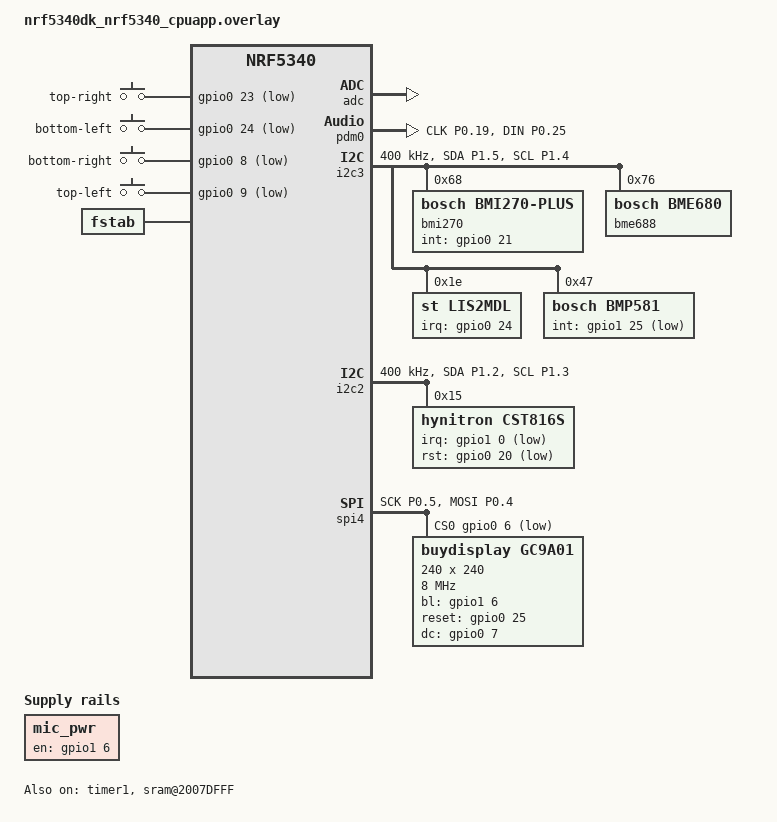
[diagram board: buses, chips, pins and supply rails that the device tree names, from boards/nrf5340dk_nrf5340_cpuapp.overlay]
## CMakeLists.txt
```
cmake_minimum_required(VERSION 3.20.0)

# Apply patches before build
function(apply_patches patch_dir target_dir)
    file(GLOB_RECURSE files RELATIVE ${CMAKE_SOURCE_DIR} "${patch_dir}/*.patch")
    foreach(file ${files})
        execute_process(
            COMMAND git apply --reverse --check ${CMAKE_CURRENT_SOURCE_DIR}/${file} --unsafe-paths
            WORKING_DIRECTORY ${target_dir}
            RESULT_VARIABLE patch_already_applied
            OUTPUT_QUIET
            ERROR_QUIET
        )
        if(patch_already_applied EQUAL 0)
            message("Patch already applied: ${file}")
        else()
            message("Applying patch: ${file}")
            execute_process(
                COMMAND git apply ${CMAKE_CURRENT_SOURCE_DIR}/${file} --unsafe-paths
                WORKING_DIRECTORY ${target_dir}
                RESULT_VARIABLE patch_apply_result
            )
            if(NOT patch_apply_result EQUAL 0)
                message(FATAL_ERROR "Failed to apply patch: ${file}")
            endif()
        endif()
    endforeach()
endfunction()

apply_patches("patches/zephyr" $ENV{ZEPHYR_BASE})
apply_patches("patches/ext_drivers" ${CMAKE_SOURCE_DIR}/src/ext_drivers)

# Get the target hardware
string(REGEX MATCH "zswatch@([0-9]+)/nrf5340.*" ZSWATCH_BOARD "${BOARD}")
if(ZSWATCH_BOARD)
    string(CONCAT VERSION_STRING "\"" ${CMAKE_MATCH_1} "\"")
    set(CONFIG_ZSWATCH_PCB_REV ${CMAKE_MATCH_1} CACHE INTERNAL "")
    set(CONFIG_BT_DIS_HW_REV_STR ${VERSION_STRING} CACHE INTERNAL "")

    message("PCB revision: " ${CONFIG_ZSWATCH_PCB_REV})
endif()

set(BOARD_ROOT ${CMAKE_CURRENT_SOURCE_DIR})

macro(app_set_runner_args)
    if (CONFIG_BOARD_ZSWATCH_NRF5340_CPUAPP AND CONFIG_BOARD_REVISION STREQUAL "5") 
        board_runner_args(nrfjprog "--qspiini=${CMAKE_CURRENT_SOURCE_DIR}/qspi_mx25u51245.ini")
    elseif(CONFIG_BOARD_ZSWATCH_NRF5340_CPUAPP AND CONFIG_BOARD_REVISION STREQUAL "4")
        board_runner_args(nrfjprog "--qspiini=${CMAKE_CURRENT_SOURCE_DIR}/qspi_at25sl128a.ini")
    else ()
        message("Uploading firmware to external flash may fail. Default ini will be used.")
    endif()
endmacro()

find_package(Zephyr REQUIRED HINTS $ENV{ZEPHYR_BASE})
project(ZSWatchFW)

zephyr_compile_definitions(
  -DNRF53_ERRATA_159_ENABLE_WORKAROUND=0 # Not allowing 128MHz CPU with QPSI at same time. We take the risk of this errata that may cause currupt QPSI data.
)

add_subdirectory(drivers)
add_subdirectory(src/history)
add_subdirectory(src/applications)
add_subdirectory(src/ui/watchfaces)
add_subdirectory(src/sensors)
add_subdirectory(src/sensor_fusion)
add_subdirectory(src/events)
add_subdirectory(src/managers)
add_subdirectory(src/drivers)
add_subdirectory(src/ble)
add_subdirectory(src/images)

include_directories(src/)
include_directories(src/ui)
include_directories(src/applications)
include_directories(src/ui/watchfaces)

if (CONFIG_DT_HAS_NORDIC_NPM1300_ENABLED)
    add_subdirectory(src/fuel_gauge)
else()
    add_subdirectory(src/basic_battery)
endif()

target_sources(app PRIVATE src/zsw_clock.c)
target_sources(app PRIVATE src/main.c)
target_sources(app PRIVATE src/zsw_cpu_freq.c)
target_sources(app PRIVATE src/zsw_retained_ram_storage.c)
target_sources(app PRIVATE src/zsw_coredump.c)

target_sources(app PRIVATE src/ui/notification/zsw_popup_notifcation.c)
target_sources(app PRIVATE src/ui/popup/zsw_popup_window.c)
target_sources(app PRIVATE src/ui/utils/zsw_ui_utils.c)

target_sources(app PRIVATE src/ui/watchfaces/zsw_watchface_dropdown_ui.c)

target_sources_ifdef(CONFIG_SPI_FLASH_LOADER app PRIVATE src/filesystem/zsw_rtt_flash_loader.c)
target_sources_ifdef(CONFIG_FILE_SYSTEM_LITTLEFS app PRIVATE src/filesystem/zsw_filesystem.c)
target_sources_ifdef(CONFIG_FILE_SYSTEM app PRIVATE src/filesystem/zsw_custom_fs.c)

target_sources_ifdef(CONFIG_RTC_ALARM app PRIVATE src/zsw_alarm.c)

target_compile_definitions(app PRIVATE _POSIX_C_SOURCE=200809L)

FILE(GLOB events_sources src/events/*.c)
target_sources(app PRIVATE ${events_sources})

add_compile_definitions(LV_LVGL_H_INCLUDE_SIMPLE)

file(GLOB ext_fs_files "src/images/binaries/S/*.*")
list(LENGTH ext_fs_files num_ext_fs_files)
add_compile_definitions(NUM_RAW_FS_FILES=${num_ext_fs_files})
message("Number of external filesystem files:" ${num_ext_fs_files})

# TODO fix all of them. New since NCS 2.7
set_target_properties(app PROPERTIES COMPILE_FLAGS -Wno-double-promotion)
zephyr_compile_options(-Wno-double-promotion)


# XIP Code Relocation
# Placing the mcumgr code in external flash causes QSPI assert. For now keeping it in iinternal flash.
zephyr_code_relocate(LIBRARY subsys__mgmt__mcumgr__mgmt LOCATION EXTFLASH_TEXT NOCOPY)
zephyr_code_relocate(LIBRARY subsys__mgmt__mcumgr__util LOCATION EXTFLASH_TEXT NOCOPY)
zephyr_code_relocate(LIBRARY subsys__mgmt__mcumgr__smp LOCATION EXTFLASH_TEXT NOCOPY)
zephyr_code_relocate(LIBRARY subsys__mgmt__mcumgr__transport LOCATION EXTFLASH_TEXT NOCOPY)
zephyr_code_relocate(LIBRARY subsys__mgmt__mcumgr__grp__img_mgmt LOCATION EXTFLASH_TEXT NOCOPY)
zephyr_code_relocate(LIBRARY subsys__mgmt__mcumgr__grp__os_mgmt LOCATION EXTFLASH_TEXT NOCOPY)

zephyr_code_relocate(LIBRARY modules__lvgl LOCATION EXTFLASH_TEXT NOCOPY)
zephyr_code_relocate(LIBRARY modules__lvgl LOCATION RAM_DATA)

zephyr_code_relocate(LIBRARY drivers__bluetooth LOCATION EXTFLASH_TEXT NOCOPY)
zephyr_code_relocate(LIBRARY drivers__bluetooth LOCATION RAM_DATA)

#zephyr_code_relocate(LIBRARY subsys__bluetooth__host LOCATION EXTFLASH_TEXT NOCOPY)
#zephyr_code_relocate(LIBRARY subsys__bluetooth__host LOCATION RAM_DATA)

zephyr_code_relocate(LIBRARY subsys__bluetooth__crypto LOCATION EXTFLASH_TEXT NOCOPY)
zephyr_code_relocate(LIBRARY subsys__bluetooth__crypto LOCATION RAM_DATA)

zephyr_code_relocate(LIBRARY drivers__usb__device LOCATION EXTFLASH_TEXT NOCOPY)
zephyr_code_relocate(LIBRARY drivers__usb__device LOCATION RAM_DATA)

zephyr_code_relocate(LIBRARY drivers__usb__common__nrf_usbd_common LOCATION EXTFLASH_TEXT NOCOPY)
zephyr_code_relocate(LIBRARY drivers__usb__common__nrf_usbd_common LOCATION RAM_DATA)

zephyr_code_relocate(LIBRARY drivers__sensor__bosch__bme680 LOCATION EXTFLASH_TEXT NOCOPY)
zephyr_code_relocate(LIBRARY drivers__sensor__bosch__bme680 LOCATION RAM_DATA)

zephyr_code_relocate(LIBRARY drivers__sensor__st__lis2mdl LOCATION EXTFLASH_TEXT NOCOPY)
zephyr_code_relocate(LIBRARY drivers__sensor__st__lis2mdl LOCATION RAM_DATA)

zephyr_code_relocate(LIBRARY drivers__sensor__st__stmemsc LOCATION EXTFLASH_TEXT NOCOPY)
zephyr_code_relocate(LIBRARY drivers__sensor__st__stmemsc LOCATION RAM_DATA)
```

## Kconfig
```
menu "Zephyr Kernel"
    source "Kconfig.zephyr"
endmenu

menu "ZSWatch"
    config ZSWATCH_PCB_REV
        int
    prompt "ZSWatch PCB revision"
    default 3

    menu "Applications"
        config APPLICATIONS_USE_2048
            bool
        prompt "Activate the application '2048'"
        default n

        config APPLICATIONS_USE_ACCELEROMETER
            bool
        prompt "Activate the application 'Accelerometer'"
        default n

        config APPLICATIONS_USE_BATTERY
            bool
        prompt "Activate the application 'Battery'"
        default n

        config APPLICATIONS_USE_COMPASS
            bool
        prompt "Activate the application 'Compass'"
        default n

        config APPLICATIONS_USE_INFO
            bool
        prompt "Activate the application 'Info'"
        default n

        config APPLICATIONS_USE_QR_CODE
            bool
        prompt "Activate the application 'QR-Code'"
        default y if LV_Z_USE_FILESYSTEM

        config APPLICATIONS_USE_SENSORS_SUMMARY
            bool
        prompt "Activate the application 'Sensors Summary'"
        default n

        config APPLICATIONS_USE_X_RAY
            bool
        prompt "Activate the application 'X-Ray'"
        default y if LV_Z_USE_FILESYSTEM

        config APPLICATIONS_USE_ZDS
            bool
        prompt "Activate the application 'ZDS'"
        default n
        select APPLICATIONS_USE_ACCELEROMETER

        config APPLICATIONS_USE_IAQ
            bool
        prompt "Activate the application 'IAQ'"
        depends on EXTERNAL_USE_BOSCH_BSEC && LV_Z_USE_FILESYSTEM
        default n

        config APPLICATIONS_USE_TRIVIA
            bool
        prompt "Activate the application 'Trivia'"
        default n

        config APPLICATIONS_USE_PPT_REMOTE
            bool
        prompt "Activate the application 'PPT remote'"
        default n
    endmenu

    menu "Watchface"
        config WATCHFACE_ANALOG
            bool
            prompt "Add analog watchface"
            default n

        config WATCHFACE_DIGITAL
            bool
            prompt "Add digital watchface"
            default y

        config WATCHFACE_MINIMAL
            bool
            prompt "Add minimal watchface"
            default y

        choice WATCHFACE_BACKGROUND_IMG
            bool
            prompt "Select which watchface background imgage to use. Not all watchfaces supports this."
            def_bool WATCHFACE_BACKGROUND_SPACE

        config WATCHFACE_BACKGROUND_SPACE
            prompt "Space themed background"
        config WATCHFACE_BACKGROUND_FLOWER
            prompt "Flower themed background"
        config WATCHFACE_BACKGROUND_PLANET
            prompt "Planet earth themed background"
        config WATCHFACE_BACKGROUND_NONE
            prompt "No background"
        endchoice
    endmenu

    menu "Default configuration"
        menu "Sensors Summary"
            depends on APPLICATIONS_USE_SENSORS_SUMMARY

            config DEFAULT_CONFIGURATION_SENSORS_SUMMARY_REFRESH_INTERVAL_MS
                int
            prompt "Refresh interval in milliseconds"
            default 100
        endmenu

        menu "Compass"
            depends on APPLICATIONS_USE_COMPASS

            config DEFAULT_CONFIGURATION_COMPASS_REFRESH_INTERVAL_MS
                int
            prompt "Refresh interval in milliseconds"
            default 50

            config DEFAULT_CONFIGURATION_COMPASS_CALIBRATION_TIME_S
                int
            prompt "Calibration time in seconds"
            default 30
        endmenu

        menu "Battery"
            depends on APPLICATIONS_USE_BATTERY

            config DEFAULT_CONFIGURATION_BATTERY_NUM_SAMPLES_MAX
                int
            prompt "Maximum number of samples"
            default 100

            config DEFAULT_CONFIGURATION_BATTERY_SAMPLE_INTERVAL_MINUTES
                int
            prompt "Battery sample interval in minutes"
            default 30
        endmenu

        menu "Power Management"
            config POWER_MANAGEMENT_IDLE_TIMEOUT_SECONDS
                int
            prompt "Idle timeout in seconds"
            default 20
        endmenu
    endmenu

    menu "External"
        choice EXTERNAL_BOSCH_SENSOR
            bool
            prompt "Select the function for the Bosch environment sensor."
            help
                You have to disable the BME680 option in the Zephyr configuration to enable the Bosch BSEC option.
            def_bool EXTERNAL_USE_BOSCH_BME688

        config EXTERNAL_USE_BOSCH_BSEC
            prompt "Use Bosch BSEC library"
            depends on !BME680
            select BME68X_EXT_IAQ

        config EXTERNAL_USE_BOSCH_BME688
            prompt "Use standard BME680 driver from Zephyr"
        endchoice
    endmenu

    menu "BLE"
        config BLE_DISABLE_PAIRING_REQUIRED
            bool
        prompt "Disable encryption required for BLE connection (pairing/bonding)"
        default n
        help
            "Disable encryption for BLE connection (pairing/bonding). Used only for debugging purposes."
    endmenu
    
    menu "SPI RTT Flash Loader"
        config SPI_FLASH_LOADER
            bool
        prompt "Enable SPI flash loader"
        default n
        select USE_SEGGER_RTT
        #select SEGGER_RTT_MODE_BLOCK_IF_FIFO_FULL
        help
            "Enable SPI flash loader"

        if SPI_FLASH_LOADER
            config ERASE_PROGRESSIVELY
                bool
            depends on SPI_FLASH_LOADER
            prompt "Erase sectors one by one when writing instead of full partition before starting."
            default y
            help
                "If not writing to the full partition this will be faster"

            config RTT_TRANSFER_CHANNEL
                int
            depends on SPI_FLASH_LOADER
            prompt "The RTT channel to use for transfer of data to and form flash"
            default 2
            help
                "If RTT logging is enabled, channel 0 is used for this, hence avoid 1 in this scenario."
        endif
    endmenu

    menu "Sensor Fusion"
        config SENSOR_FUSION_INCLUDE_MAGNETOMETER
            bool
        prompt "Include Magnetometer reading in sensor fusion algorithm"
        default y
        help
            "If the magnetometer is not well calibrated, you must disable this option."

        config SEND_SENSOR_READING_OVER_RTT
            bool
        prompt "Log sensor fusion reading to RTT"
        default 1
        help
            "Python script can be used to read, analyze the RTT channel and plot the sensor fusion reading."

        if SEND_SENSOR_READING_OVER_RTT
            config SENSOR_LOG_RTT_TRANSFER_CHANNEL
                int
            prompt "The RTT channel to use for transfer of sensor fusion reading"
            default 1
            help
                "If RTT logging is enabled"
        endif
    endmenu

    menu "ZSWatch Init Priorities"
    config ZSW_DRIVER_INIT_PRIORITY
        int
        default 85
    endmenu

    menu "Custom drivers"
        rsource "drivers/Kconfig"
    endmenu

    menu "Logging"
        module = ZSW_APP
        module-str = ZSW_APP
        source "subsys/logging/Kconfig.template.log_config"

        rsource "src/sensors/Kconfig"
        rsource "src/sensor_fusion/Kconfig"
        rsource "src/ble/Kconfig"
        rsource "src/applications/settings/Kconfig"
        rsource "src/applications/template/Kconfig"
        rsource "src/applications/iaq/Kconfig"
        rsource "src/applications/notification/Kconfig"
        rsource "src/applications/trivia/Kconfig"
        rsource "src/applications/ppt_remote/Kconfig"
    endmenu
endmenu
```

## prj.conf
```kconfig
CONFIG_MAIN_STACK_SIZE=2048
CONFIG_SYSTEM_WORKQUEUE_STACK_SIZE=10000
CONFIG_HEAP_MEM_POOL_SIZE=25000
CONFIG_CBPRINTF_FP_SUPPORT=y
CONFIG_DEBUG_THREAD_INFO=y

CONFIG_ASSERT=y
CONFIG_REBOOT=y
CONFIG_DISPLAY=y
CONFIG_BASE64=y

CONFIG_RETAINED_MEM=y
CONFIG_RETENTION=y
CONFIG_RETENTION_BOOT_MODE=y

CONFIG_I2C=y
CONFIG_SENSOR=y
CONFIG_ADC=y
CONFIG_LIS2MDL=y
CONFIG_LIS2MDL_MAG_ODR_RUNTIME=y
CONFIG_LIS2MDL_TRIGGER_OWN_THREAD=y

CONFIG_PINCTRL=y
CONFIG_PM_DEVICE=y
CONFIG_PM_DEVICE_RUNTIME=y

CONFIG_PWM=y

CONFIG_COUNTER=y
CONFIG_NRFX_TIMER1=y

CONFIG_SPI=y
CONFIG_GC9A01=y
CONFIG_INPUT=y
CONFIG_REGULATOR=y
CONFIG_REGULATOR_FIXED=y

# LVGL configuration
CONFIG_LVGL=y
CONFIG_LV_Z_FLUSH_THREAD=y
CONFIG_LV_Z_FLUSH_THREAD_PRIORITY=0
CONFIG_LV_FONT_MONTSERRAT_10=y
CONFIG_LV_FONT_MONTSERRAT_12=y
CONFIG_LV_FONT_MONTSERRAT_14=y
CONFIG_LV_FONT_MONTSERRAT_16=y
CONFIG_LV_FONT_MONTSERRAT_18=y
CONFIG_LV_FONT_MONTSERRAT_20=y
CONFIG_LV_Z_POINTER_INPUT_MSGQ_COUNT=200
CONFIG_LV_Z_POINTER_INPUT=y

CONFIG_LV_CACHE_DEF_SIZE=10
CONFIG_LV_IMAGE_HEADER_CACHE_DEF_CNT=10
CONFIG_LV_USE_CUSTOM_SPRINTF=y

CONFIG_LV_Z_DOUBLE_VDB=y
CONFIG_LV_Z_VDB_SIZE=10
CONFIG_LV_DEF_REFR_PERIOD=30

CONFIG_LV_THEME_DEFAULT_DARK=y
CONFIG_LV_USE_THEME_DEFAULT=y

CONFIG_LV_COLOR_16_SWAP=y
CONFIG_LV_COLOR_DEPTH_16=y

# LVGL Size optimizations
CONFIG_LV_CONF_MINIMAL=y
CONFIG_LV_LABEL_TEXT_SELECTION=n
CONFIG_LV_LABEL_LONG_TXT_HINT=n
CONFIG_LV_USE_LOG=y
CONFIG_LV_USE_DROPDOWN=y
CONFIG_LV_USE_LINE=y
CONFIG_LV_USE_SLIDER=y
CONFIG_LV_USE_SWITCH=y
CONFIG_LV_USE_FLEX=y
CONFIG_LV_USE_ANIMIMG=y
CONFIG_LV_USE_CHART=y
CONFIG_LV_USE_LED=y
CONFIG_LV_USE_MENU=y
CONFIG_LV_USE_MSGBOX=y
CONFIG_LV_USE_SPINNER=y
CONFIG_LV_USE_TILEVIEW=y
CONFIG_LV_USE_GIF=y
CONFIG_LV_USE_LABEL=y
CONFIG_LV_USE_IMAGE=y
CONFIG_LV_USE_ARC=y
CONFIG_LV_USE_BUTTON=y
CONFIG_LV_USE_BUTTONMATRIX=y
CONFIG_LV_USE_IMAGEBUTTON=y
CONFIG_LV_USE_SCALE=y
CONFIG_LV_USE_ASSERT_NULL=y
CONFIG_LV_USE_ASSERT_MALLOC=y
CONFIG_LV_FONT_DEFAULT_MONTSERRAT_14=y
CONFIG_LV_WIDGETS_HAS_DEFAULT_VALUE=y
CONFIG_LV_TXT_ENC_UTF8=y

CONFIG_LV_DRAW_SW_SUPPORT_RGB565=y
CONFIG_LV_DRAW_SW_SUPPORT_RGB565A8=y
CONFIG_LV_DRAW_SW_SUPPORT_RGB888=n
CONFIG_LV_DRAW_SW_SUPPORT_XRGB8888=n
CONFIG_LV_DRAW_SW_SUPPORT_ARGB8888=n
CONFIG_LV_DRAW_SW_SUPPORT_L8=n
CONFIG_LV_DRAW_SW_SUPPORT_AL88=n
CONFIG_LV_DRAW_SW_SUPPORT_A8=n
CONFIG_LV_DRAW_SW_SUPPORT_I1=n

#
# Memory settings
#
CONFIG_LV_Z_MEM_POOL_SIZE=110000
# end of Memory settings

# NVS
CONFIG_FLASH=y
CONFIG_FLASH_MAP=y
CONFIG_MPU_ALLOW_FLASH_WRITE=y
CONFIG_FLASH_PAGE_LAYOUT=y
CONFIG_FLASH_MAP_LABELS=y

CONFIG_SETTINGS=y
CONFIG_NVS=y

# Bluetooth
CONFIG_BT=y
CONFIG_BT_HCI=y
CONFIG_BT_HCI_ACL_FLOW_CONTROL=y
CONFIG_BT_CTLR=n
# Enable chaining of multiple CTEs in periodic advertising
CONFIG_BT_SMP=y
CONFIG_BT_PERIPHERAL=y
CONFIG_BT_DIS=y
CONFIG_BT_DIS_PNP=n
CONFIG_BT_DIS_HW_REV=y
CONFIG_BT_DIS_MODEL="ZSWatch"
CONFIG_BT_BAS=y
CONFIG_BT_HRS=n
CONFIG_BT_DEVICE_NAME="ZSWatch"
CONFIG_BT_DEVICE_APPEARANCE=194
CONFIG_BT_KEYS_OVERWRITE_OLDEST=y
CONFIG_BT_SETTINGS=y
CONFIG_BT_MAX_PAIRED=5
CONFIG_BT_MAX_CONN=1
CONFIG_BT_GATT_CLIENT=y
CONFIG_BT_GATT_CACHING=y
CONFIG_BT_GATT_NOTIFY_MULTIPLE=y

CONFIG_BT_BROADCASTER=y
CONFIG_BT_SMP_ALLOW_UNAUTH_OVERWRITE=y

CONFIG_BT_L2CAP_TX_MTU=498
CONFIG_BT_BUF_ACL_RX_SIZE=502
CONFIG_BT_BUF_ACL_TX_SIZE=251
CONFIG_BT_L2CAP_TX_MTU=247

CONFIG_BT_BUF_ACL_RX_COUNT_EXTRA=50

CONFIG_BT_L2CAP_TX_BUF_COUNT=10
CONFIG_BT_CONN_TX_MAX=15
CONFIG_BT_BUF_ACL_TX_COUNT=15

CONFIG_BT_DATA_LEN_UPDATE=y
CONFIG_BT_AUTO_PHY_UPDATE=y
CONFIG_BT_USER_PHY_UPDATE=y
CONFIG_BT_USER_DATA_LEN_UPDATE=y
CONFIG_BT_AUTO_DATA_LEN_UPDATE=n
CONFIG_BT_GAP_AUTO_UPDATE_CONN_PARAMS=y
CONFIG_BT_GAP_PERIPHERAL_PREF_PARAMS=y
CONFIG_BT_PERIPHERAL_PREF_MIN_INT=24
CONFIG_BT_PERIPHERAL_PREF_MAX_INT=40
CONFIG_BT_PERIPHERAL_PREF_LATENCY=0
CONFIG_BT_PERIPHERAL_PREF_TIMEOUT=200

# iOS ble GATT server
CONFIG_BT_GATTP=y
CONFIG_BT_GATT_DM=y
CONFIG_BT_AMS_CLIENT=y
CONFIG_BT_ANCS_CLIENT=y
CONFIG_BT_CTS_CLIENT=y

# Don't change this
CONFIG_BT_RECV_WORKQ_SYS=y

CONFIG_PICOLIBC=y
CONFIG_PICOLIBC_IO_FLOAT=y
CONFIG_POSIX_API=y

# By default disable UART to save power

CONFIG_ZBUS=y
CONFIG_ZBUS_RUNTIME_OBSERVERS=y
CONFIG_ZBUS_CHANNEL_NAME=y
CONFIG_ZBUS_OBSERVER_NAME=y
CONFIG_ZBUS_CHANNELS_SYS_INIT_PRIORITY=1

# Choose one or many of below
CONFIG_WATCHFACE_DIGITAL=y
CONFIG_WATCHFACE_MINIMAL=n

# Choose one of below
CONFIG_WATCHFACE_BACKGROUND_SPACE=y
CONFIG_WATCHFACE_BACKGROUND_FLOWER=n
CONFIG_WATCHFACE_BACKGROUND_PLANET=n
CONFIG_WATCHFACE_BACKGROUND_NONE=n

# Default watch
CONFIG_POWER_MANAGEMENT_IDLE_TIMEOUT_SECONDS=20
CONFIG_APPLICATIONS_CONFIGURATION_SENSORS_SUMMARY_REFRESH_INTERVAL_MS=100

# CST816S
CONFIG_INPUT_CST816S_INTERRUPT=y
CONFIG_INPUT_CST816S=n
CONFIG_INPUT_MODIFIED_CST816S=y

# BMI270
CONFIG_BMI270_PLUS=y
CONFIG_BMI270_PLUS_TRIGGER_GLOBAL_THREAD=y

CONFIG_RESET_ON_FATAL_ERROR=y

CONFIG_DEBUG_COREDUMP=y
CONFIG_DEBUG_COREDUMP_MEMORY_DUMP_MIN=y
CONFIG_RETENTION_MUTEX_FORCE_DISABLE=y
CONFIG_RETAINED_MEM_MUTEX_FORCE_DISABLE=y
CONFIG_RETENTION_BUFFER_SIZE=256

CONFIG_CJSON_LIB=y
CONFIG_MPU=y

CONFIG_CODE_DATA_RELOCATION=n

CONFIG_APPLICATIONS_USE_2048=n # Not working with LVGL 9.3
```

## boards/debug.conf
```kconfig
CONFIG_BLE_DISABLE_PAIRING_REQUIRED=y
CONFIG_SENSOR_LOG_LEVEL_WRN=y
CONFIG_THREAD_NAME=y
CONFIG_PRINTK=y

# SEGGER RTT logging instead of UART
CONFIG_LOG_PRINTK=y
CONFIG_LOG=y
CONFIG_LOG_INFO_COLOR_GREEN=y
CONFIG_DEBUG_OPTIMIZATIONS=y
CONFIG_USE_SEGGER_RTT=y
CONFIG_LOG_BACKEND_RTT=y
CONFIG_LOG_BACKEND_RTT_MODE_BLOCK=y
CONFIG_LOG_BUFFER_SIZE=4096
CONFIG_LOG_BACKEND_RTT_OUTPUT_BUFFER_SIZE=128
CONFIG_LOG_BLOCK_IN_THREAD=y
# End of SEGGER RTT

# Comment out to show FPS counter
#CONFIG_LV_USE_PERF_MONITOR=y
#CONFIG_LV_PERF_MONITOR_ALIGN_RIGHT_MID=y

CONFIG_ZSW_APP_LOG_LEVEL_WRN=y
CONFIG_ZSW_SENSORS_LOG_LEVEL_WRN=y
CONFIG_ZSW_BLE_LOG_LEVEL_WRN=y
CONFIG_ZSW_SETTINGS_APP_LOG_LEVEL_WRN=y
CONFIG_ZSW_APP_LOG_LEVEL_DBG=y
CONFIG_MISC_ENABLE_SYSTEM_RESET=y

CONFIG_LV_USE_LOG=y
CONFIG_LV_LOG_LEVEL_WARN=y
```

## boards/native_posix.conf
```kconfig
CONFIG_ZSWATCH_PCB_REV=3
CONFIG_BT_DIS_HW_REV_STR="3"

CONFIG_FLASH_SIMULATOR=y

CONFIG_I2C=n
CONFIG_PWM=n
CONFIG_SENSOR=n
CONFIG_ADC=n
CONFIG_BMI270_PLUS=n
CONFIG_LIS2MDL=n
CONFIG_LIS2MDL_MAG_ODR_RUNTIME=n
CONFIG_BME680=n
CONFIG_MAX30101=n
CONFIG_APDS9306=n
CONFIG_APDS9306_IS_APDS9306_065=n
CONFIG_MAX30101_MULTI_LED_MODE=n
CONFIG_APDS9306=n
CONFIG_PINCTRL=n
CONFIG_TEST_RANDOM_GENERATOR=y
CONFIG_REGULATOR=y

CONFIG_GPIO=y
CONFIG_INPUT=y
CONFIG_INPUT_LONGPRESS=n
CONFIG_INPUT_SDL_TOUCH=y
CONFIG_GPIO_EMUL_SDL=y

CONFIG_RTC=y
CONFIG_RTC_ALARM=y
CONFIG_RTC_EMUL=y

CONFIG_SPI=n
CONFIG_GC9A01=n
CONFIG_INPUT_MODIFIED_CST816S=n
CONFIG_INPUT_CST816S_INTERRUPT=n
CONFIG_REGULATOR_FIXED=n

CONFIG_SDL_DISPLAY_DEFAULT_PIXEL_FORMAT_RGB_565=y

CONFIG_NEWLIB_LIBC=n
CONFIG_NEWLIB_LIBC_FLOAT_PRINTF=n
CONFIG_POSIX_API=n

CONFIG_CONSOLE=y

CONFIG_BLE_DISABLE_PAIRING_REQUIRED=y
CONFIG_THREAD_NAME=y
CONFIG_PRINTK=y

CONFIG_LOG_PRINTK=y
CONFIG_LOG=y
CONFIG_DEBUG_OPTIMIZATIONS=y

CONFIG_SPI_FLASH_LOADER=n

CONFIG_BT_EXT_ADV=n

CONFIG_SDL_DISPLAY_ZOOM_PCT=200
CONFIG_SDL_DISPLAY_USE_HARDWARE_ACCELERATOR=n
CONFIG_LV_Z_FLUSH_THREAD=n


CONFIG_FILE_SYSTEM=y
CONFIG_FILE_SYSTEM_LITTLEFS=y
CONFIG_LV_Z_USE_FILESYSTEM=y
CONFIG_LV_IMG_CACHE_DEF_SIZE=10

CONFIG_FS_LITTLEFS_FC_HEAP_SIZE=16384
CONFIG_FS_LITTLEFS_NUM_FILES=64

# FOTA 
CONFIG_BOOTLOADER_MCUBOOT=y
CONFIG_NCS_SAMPLE_MCUMGR_BT_OTA_DFU=y

CONFIG_MCUMGR=y
CONFIG_MCUMGR_TRANSPORT_WORKQUEUE_STACK_SIZE=8096
CONFIG_SHELL=y
CONFIG_CONSOLE=y
#CONFIG_MCUMGR_TRANSPORT_UART=y
CONFIG_MCUMGR_GRP_OS=y
CONFIG_MCUMGR_GRP_OS_TASKSTAT=y
CONFIG_MCUMGR_GRP_FS=y
CONFIG_MCUMGR_GRP_SHELL=y

CONFIG_MCUMGR_GRP_FS_LOG_LEVEL_DBG=y
# Enable MCUMGR management for both OS and Images
CONFIG_MCUMGR_GRP_OS=y
CONFIG_MCUMGR_GRP_IMG=y

# Configure MCUMGR transport to UART
#CONFIG_MCUMGR_TRANSPORT_UART=y

# Dependencies
# Configure dependencies for CONFIG_MCUMGR  
CONFIG_NET_BUF=y
CONFIG_ZCBOR=y
CONFIG_CRC=y

# Configure dependencies for CONFIG_MCUMGR_GRP_IMG  
CONFIG_FLASH=y
CONFIG_IMG_MANAGER=y

# Configure dependencies for CONFIG_IMG_MANAGER  
CONFIG_STREAM_FLASH=y
CONFIG_FLASH_MAP=y

# Configure dependencies for CONFIG_MCUMGR_TRANSPORT_UART 
CONFIG_BASE64=y

CONFIG_MCUBOOT_BOOTUTIL_LIB=y

CONFIG_BT_GATT_DYNAMIC_DB=y
CONFIG_MCUMGR_TRANSPORT_BT_DYNAMIC_SVC_REGISTRATION=y
CONFIG_MCUMGR_MGMT_NOTIFICATION_HOOKS=y

CONFIG_SHELL=y
CONFIG_SHELL_STACK_SIZE=4096
CONFIG_MCUMGR_TRANSPORT_WORKQUEUE_STACK_SIZE=4096
#CONFIG_SHELL_BACKEND_SERIAL=y
CONFIG_MCUMGR_TRANSPORT_SHELL=y

# mcumgr-cli application doesn't accepts log in the channel it uses
CONFIG_SHELL_LOG_BACKEND=n

#CONFIG_CONSOLE=y
#CONFIG_UART_CONSOLE=y
#CONFIG_UART_CONSOLE_MCUMGR=y
CONFIG_SHELL_BACKEND_DUMMY=y
```

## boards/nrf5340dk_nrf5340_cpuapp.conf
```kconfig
#---------------
# FLASH
#-----------------
CONFIG_FLASH=y
CONFIG_FLASH_PAGE_LAYOUT=y
CONFIG_STREAM_FLASH=y
CONFIG_FLASH_MAP=y
CONFIG_NVS=y
CONFIG_NORDIC_QSPI_NOR=y
CONFIG_NORDIC_QSPI_NOR_FLASH_LAYOUT_PAGE_SIZE=4096

CONFIG_MPU_ALLOW_FLASH_WRITE=y

CONFIG_FILE_SYSTEM=y
CONFIG_FILE_SYSTEM_LITTLEFS=y
CONFIG_LV_Z_USE_FILESYSTEM=y
CONFIG_LV_IMG_CACHE_DEF_SIZE=10

CONFIG_FS_LITTLEFS_FC_HEAP_SIZE=16384

CONFIG_SPI_FLASH_LOADER=y

# NCS Partition Manager
# Make sure size matches dts
CONFIG_PM_PARTITION_REGION_SETTINGS_STORAGE_EXTERNAL=y
CONFIG_PM_PARTITION_SIZE_SETTINGS_STORAGE=0x100000
CONFIG_PM_PARTITION_REGION_LITTLEFS_EXTERNAL=y

# BME688 
CONFIG_BME680=y


#---------------
# FLASH
#-----------------
CONFIG_FLASH=y
CONFIG_FLASH_PAGE_LAYOUT=y
CONFIG_STREAM_FLASH=y
CONFIG_FLASH_MAP=y
CONFIG_NVS=y
CONFIG_NORDIC_QSPI_NOR=y
CONFIG_NORDIC_QSPI_NOR_FLASH_LAYOUT_PAGE_SIZE=4096

CONFIG_MPU_ALLOW_FLASH_WRITE=y

CONFIG_FILE_SYSTEM=y
CONFIG_FILE_SYSTEM_LITTLEFS=y
CONFIG_LV_Z_USE_FILESYSTEM=y
CONFIG_LV_IMG_CACHE_DEF_SIZE=10

CONFIG_FS_LITTLEFS_FC_HEAP_SIZE=16384

CONFIG_PM_PARTITION_REGION_SETTINGS_STORAGE_EXTERNAL=y
CONFIG_PM_PARTITION_SIZE_SETTINGS_STORAGE=0x100000

# Treat nRF5340 dk as a rev 4 due to it mostly being used to indicate
# how external flash shall be utilized. nRF5340dk has QSPI flash, hence
# similar to rev 4.
CONFIG_ZSWATCH_PCB_REV=4

# Mic
CONFIG_AUDIO=y
CONFIG_AUDIO_DMIC=y
```

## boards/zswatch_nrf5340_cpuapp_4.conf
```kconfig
#---------------
# FLASH
#-----------------
CONFIG_FLASH=y
CONFIG_FLASH_PAGE_LAYOUT=y
CONFIG_STREAM_FLASH=y
CONFIG_FLASH_MAP=y
CONFIG_NVS=y
CONFIG_NORDIC_QSPI_NOR=y
CONFIG_NORDIC_QSPI_NOR_FLASH_LAYOUT_PAGE_SIZE=4096
CONFIG_NORDIC_QSPI_NOR_INIT_PRIORITY=1

CONFIG_MPU_ALLOW_FLASH_WRITE=y

CONFIG_FILE_SYSTEM=y
CONFIG_FILE_SYSTEM_LITTLEFS=y
CONFIG_LV_Z_USE_FILESYSTEM=y

CONFIG_FS_LITTLEFS_FC_HEAP_SIZE=16384
CONFIG_FS_LITTLEFS_NUM_FILES=64

# APDS9306
CONFIG_APDS9306=y
CONFIG_APDS9306_IS_APDS9306_065=y

# NCS External flash
# The sizes here need to match dts
CONFIG_PM_OVERRIDE_EXTERNAL_DRIVER_CHECK=y
CONFIG_PM_PARTITION_REGION_SETTINGS_STORAGE_EXTERNAL=y
CONFIG_PM_PARTITION_SIZE_SETTINGS_STORAGE=0x100000

CONFIG_PM_PARTITION_REGION_LITTLEFS_EXTERNAL=y
CONFIG_PM_PARTITION_SIZE_LITTLEFS=0x200000

CONFIG_DEBUG_COREDUMP_BACKEND_OTHER=y

CONFIG_STORE_IMAGES_EXTERNAL_FLASH=y

# FOTA 
CONFIG_NCS_SAMPLE_MCUMGR_BT_OTA_DFU=y

CONFIG_MCUMGR=y
CONFIG_MCUMGR_GRP_OS=y
CONFIG_MCUMGR_GRP_OS_TASKSTAT=y
CONFIG_MCUMGR_GRP_FS=y
CONFIG_MCUMGR_GRP_SHELL=y

CONFIG_BT_GATT_DYNAMIC_DB=y
CONFIG_MCUMGR_TRANSPORT_BT_DYNAMIC_SVC_REGISTRATION=y
CONFIG_MCUMGR_MGMT_NOTIFICATION_HOOKS=y
CONFIG_MCUMGR_GRP_IMG_UPLOAD_CHECK_HOOK=y
CONFIG_MCUMGR_GRP_IMG_IMAGE_SLOT_STATE_HOOK=y
CONFIG_MCUMGR_GRP_IMG_STATUS_HOOKS=y

CONFIG_MCUMGR_GRP_FS_LOG_LEVEL_DBG=y
# Enable MCUMGR management for both OS and Images
CONFIG_MCUMGR_GRP_OS=y
CONFIG_MCUMGR_GRP_IMG=y

# Configure MCUMGR transport to UART
CONFIG_MCUMGR_TRANSPORT_BT=y

# Dependencies
# Configure dependencies for CONFIG_MCUMGR  
CONFIG_NET_BUF=y
CONFIG_ZCBOR=y
CONFIG_CRC=y

# Configure dependencies for CONFIG_MCUMGR_GRP_IMG  
CONFIG_FLASH=y
CONFIG_IMG_MANAGER=y

# Configure dependencies for CONFIG_IMG_MANAGER  
CONFIG_STREAM_FLASH=y
CONFIG_FLASH_MAP=y

CONFIG_BASE64=y

# Enable Shell with Dummy backend
CONFIG_SHELL=y
CONFIG_SHELL_BACKEND_SERIAL=n
CONFIG_SHELL_BACKEND_DUMMY=y

# Enable MCUmgr and Shell transport
CONFIG_MCUMGR=y
CONFIG_MCUMGR_TRANSPORT_WORKQUEUE_STACK_SIZE=8096
CONFIG_BASE64=y
CONFIG_MCUMGR_TRANSPORT_SHELL=n
CONFIG_MCUMGR_TRANSPORT_DUMMY=y

# mcumgr-cli application doesn't accept log in the channel it uses
CONFIG_SHELL_LOG_BACKEND=n

# XIP
CONFIG_HAVE_CUSTOM_LINKER_SCRIPT=y
CONFIG_CODE_DATA_RELOCATION=y
CONFIG_BUILD_NO_GAP_FILL=y
CONFIG_CUSTOM_LINKER_SCRIPT="linker_arm_extxip.ld"
CONFIG_FLASH_INIT_PRIORITY=40
CONFIG_NORDIC_QSPI_NOR_XIP=y
```

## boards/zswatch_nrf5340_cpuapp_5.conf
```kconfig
# FLASH
CONFIG_FLASH=y
CONFIG_FLASH_PAGE_LAYOUT=y
CONFIG_STREAM_FLASH=y
CONFIG_FLASH_MAP=y
CONFIG_NORDIC_QSPI_NOR=y
CONFIG_NORDIC_QSPI_NOR_FLASH_LAYOUT_PAGE_SIZE=4096
CONFIG_NORDIC_QSPI_NOR_INIT_PRIORITY=1

CONFIG_MPU_ALLOW_FLASH_WRITE=y

CONFIG_FILE_SYSTEM=y
CONFIG_FILE_SYSTEM_LITTLEFS=y
CONFIG_LV_Z_USE_FILESYSTEM=y

CONFIG_FS_LITTLEFS_FC_HEAP_SIZE=16384
CONFIG_FS_LITTLEFS_NUM_FILES=64

# APDS9306
CONFIG_APDS9306=y
CONFIG_APDS9306_IS_APDS9306_065=y

# NCS External flash
# The sizes here need to match dts
CONFIG_PM_OVERRIDE_EXTERNAL_DRIVER_CHECK=y
CONFIG_PM_PARTITION_REGION_SETTINGS_STORAGE_EXTERNAL=y
CONFIG_PM_PARTITION_SIZE_SETTINGS_STORAGE=0x100000

CONFIG_PM_PARTITION_REGION_LITTLEFS_EXTERNAL=y
CONFIG_PM_PARTITION_SIZE_LITTLEFS=0x200000

CONFIG_NRF_FUEL_GAUGE=y
CONFIG_MFD_NPM1300_INIT_PRIORITY=51
CONFIG_REGULATOR_NPM1300_COMMON_INIT_PRIORITY=52
CONFIG_REGULATOR_NPM1300_INIT_PRIORITY=53

CONFIG_SETTINGS_NVS=y
CONFIG_NVS=y

CONFIG_DEBUG_COREDUMP_BACKEND_OTHER=y

CONFIG_RTC=y
CONFIG_RTC_UPDATE=n
CONFIG_RTC_ALARM=y

# Save som flash temporary
CONFIG_APPLICATIONS_USE_QR_CODE=n
CONFIG_APPLICATIONS_USE_X_RAY=n

CONFIG_STORE_IMAGES_EXTERNAL_FLASH=y

# Enable USB subsystem
CONFIG_USB_DEVICE_STACK=y
CONFIG_SERIAL=y
CONFIG_UART_LINE_CTRL=y
CONFIG_USB_DEVICE_INITIALIZE_AT_BOOT=n

# FOTA 
CONFIG_NCS_SAMPLE_MCUMGR_BT_OTA_DFU=y

CONFIG_MCUMGR=y
CONFIG_MCUMGR_TRANSPORT_WORKQUEUE_STACK_SIZE=8096
CONFIG_SHELL=y
CONFIG_CONSOLE=y
CONFIG_MCUMGR_TRANSPORT_UART=y
CONFIG_MCUMGR_GRP_OS=y
CONFIG_MCUMGR_GRP_OS_TASKSTAT=y
CONFIG_MCUMGR_GRP_FS=y
CONFIG_MCUMGR_GRP_SHELL=y

CONFIG_BT_GATT_DYNAMIC_DB=y
CONFIG_MCUMGR_TRANSPORT_BT_DYNAMIC_SVC_REGISTRATION=y
CONFIG_MCUMGR_MGMT_NOTIFICATION_HOOKS=y
CONFIG_MCUMGR_GRP_IMG_UPLOAD_CHECK_HOOK=y
CONFIG_MCUMGR_GRP_IMG_IMAGE_SLOT_STATE_HOOK=y
CONFIG_MCUMGR_GRP_IMG_STATUS_HOOKS=y
CONFIG_MCUMGR_GRP_FS_LOG_LEVEL_DBG=y
# Enable MCUMGR management for both OS and Images
CONFIG_MCUMGR_GRP_OS=y
CONFIG_MCUMGR_GRP_IMG=y

# Configure MCUMGR transport to UART
CONFIG_MCUMGR_TRANSPORT_UART=y

# Dependencies
# Configure dependencies for CONFIG_MCUMGR  
CONFIG_NET_BUF=y
CONFIG_ZCBOR=y
CONFIG_CRC=y

# Configure dependencies for CONFIG_MCUMGR_GRP_IMG  
CONFIG_FLASH=y
CONFIG_IMG_MANAGER=y

# Configure dependencies for CONFIG_IMG_MANAGER  
CONFIG_STREAM_FLASH=y
CONFIG_FLASH_MAP=y

# Configure dependencies for CONFIG_MCUMGR_TRANSPORT_UART 
CONFIG_BASE64=y


CONFIG_SHELL=y
CONFIG_SHELL_STACK_SIZE=4096
CONFIG_MCUMGR_TRANSPORT_WORKQUEUE_STACK_SIZE=8096
CONFIG_SHELL_BACKEND_SERIAL=y
CONFIG_MCUMGR_TRANSPORT_SHELL=y

# mcumgr-cli application doesn't accepts log in the channel it uses
CONFIG_SHELL_LOG_BACKEND=n

CONFIG_CONSOLE=y
CONFIG_UART_CONSOLE=y
CONFIG_UART_CONSOLE_MCUMGR=y
CONFIG_SHELL_BACKEND_DUMMY=y

# XIP
CONFIG_HAVE_CUSTOM_LINKER_SCRIPT=y
CONFIG_CODE_DATA_RELOCATION=y
CONFIG_BUILD_NO_GAP_FILL=y
CONFIG_CUSTOM_LINKER_SCRIPT="linker_arm_extxip.ld"
CONFIG_FLASH_INIT_PRIORITY=40
CONFIG_NORDIC_QSPI_NOR_XIP=y
```

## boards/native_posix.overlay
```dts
#include <zephyr/dt-bindings/input/input-event-codes.h>

/{

    sdl_dc {
        compatible = "zephyr,sdl-dc";
        height = <240>;
        width = <240>;
    };

};

/ {
	fstab {
		compatible = "zephyr,fstab";
		lvgl_lfs: lvgl_lfs {
			compatible = "zephyr,fstab,littlefs";
			mount-point = "/lvgl_lfs";
			partition = <&lvgl_lfs_partition>;
			automount;
			read-size = <1024>;
			prog-size = <512>;
			cache-size = <4096>;
			lookahead-size = <4096>;
			block-cycles = <512>;
		};
	};
};
```

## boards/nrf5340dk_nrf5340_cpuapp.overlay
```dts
/*
 * Copyright (c) 2023 Jakob Krantz
 *
 * SPDX-License-Identifier: Apache-2.0
 */

 &pinctrl {
    // Set to I2C pins that the sensors are connected to
    i2c3_default: i2c3_default {
        group1 {
            psels = <NRF_PSEL(TWIM_SDA, 1, 5)>,
                <NRF_PSEL(TWIM_SCL, 1, 4)>;
        };
    };

    i2c3_sleep: i2c3_sleep {
        group1 {
            psels = <NRF_PSEL(TWIM_SDA, 1, 5)>,
                <NRF_PSEL(TWIM_SCL, 1, 4)>;
            low-power-enable;
        };
    };

    // Set to I2C pins that the touch screen is connected to
    i2c2_default: i2c2_default {
        group1 {
            psels = <NRF_PSEL(TWIM_SDA, 1, 2)>,
                <NRF_PSEL(TWIM_SCL, 1, 3)>;
        };
    };

    i2c2_sleep: i2c2_sleep {
        group1 {
            psels = <NRF_PSEL(TWIM_SDA, 1, 2)>,
                <NRF_PSEL(TWIM_SCL, 1, 3)>;
            low-power-enable;
        };
    };

    // Set to the pins that the display is connected to
    spi4_default: spi4_default {
        group1 {
            psels = <NRF_PSEL(SPIM_SCK, 0, 5)>,
                <NRF_PSEL(SPIM_MOSI, 0, 4)>;
        };
    };

    spi4_sleep: spi4_sleep {
        group1 {
            psels = <NRF_PSEL(SPIM_SCK, 0, 5)>,
                <NRF_PSEL(SPIM_MOSI, 0, 4)>;
            low-power-enable;
        };
    };

    pdm0_default_alt: pdm0_default_alt {
		group1 {
			psels = <NRF_PSEL(PDM_CLK, 0, 19)>,
				<NRF_PSEL(PDM_DIN, 0, 25)>;
		};
	};

};

/ {
    /delete-node/ buttons;
    
    chosen {
        zephyr,display = &gc9a01;
        zephyr,keyboard-scan = &cst816s;
        nordic,pm-ext-flash = &mx25r64;
    };

    lvgl_pointer_input: lvgl_pointer {
        compatible = "zephyr,lvgl-pointer-input";
        input = <&cst816s>;
        swap-xy;
        invert-x;
    };

    aliases {
        magn = &lis2mdl;
        accel = &bmi270;
        input = &cst816s;
        mcuboot-button0 = &button1;
        sw0 = &button4;
    };

    mic_pwr: mic-pwr-ctrl {
        compatible = "regulator-fixed";
        regulator-name = "mic-pwr-ctrl";
        enable-gpios = <&gpio1 6 GPIO_ACTIVE_HIGH>;
    };

    longpress: longpress {
        input = <&buttons>;
        compatible = "zephyr,input-longpress";
        input-codes = <INPUT_KEY_KP0>;
        short-codes = <INPUT_KEY_4>;
        long-codes = <INPUT_KEY_Y>;
        long-delay-ms = <1000>;
    };

    buttons: buttons {
        compatible = "gpio-keys";
        button1: button_1 {
            label = "top-right";
            gpios = <&gpio0 23 (GPIO_PULL_UP | GPIO_ACTIVE_LOW)>;
            zephyr,code = <INPUT_KEY_1>;
        };
        button2: button_2 {
            label = "bottom-left";
            gpios = <&gpio0 24 (GPIO_PULL_UP | GPIO_ACTIVE_LOW)>;
            zephyr,code = <INPUT_KEY_2>;
        };
        button3: button_3 {
            label = "bottom-right";
            gpios = <&gpio0 8 (GPIO_PULL_UP | GPIO_ACTIVE_LOW)>;
            zephyr,code = <INPUT_KEY_3>;
        };
        button4: button_4 {
            label = "top-left";
            gpios = <&gpio0 9 (GPIO_PULL_UP | GPIO_ACTIVE_LOW)>;
            zephyr,code = <INPUT_KEY_KP0>;
        };
    };
};

&adc {
    status = "okay";
};

&gpiote {
    status = "okay";
};

&gpio0 {
    status = "okay";
    sense-edge-mask = < 0xffffffff >;
};

&gpio1 {
    status = "okay";
};

&timer1 {
    status = "okay";
};

dmic_dev: &pdm0 {
    status = "okay";
    pinctrl-0 = <&pdm0_default_alt>;
    pinctrl-names = "default";
    clock-source = "PCLK32M";
};

&i2c3 {
    compatible = "nordic,nrf-twim";
    status = "okay";
    clock-frequency = <I2C_BITRATE_FAST>;
    zephyr,concat-buf-size = <512>;
    pinctrl-0 = <&i2c3_default>;
    pinctrl-1 = <&i2c3_sleep>;
    pinctrl-names = "default", "sleep";

    bmi270: bmi270@68 {
        compatible = "bosch,bmi270-plus";
        reg = <0x68>;
        int-gpios = <&gpio0 21 (GPIO_PULL_DOWN | GPIO_ACTIVE_HIGH)>;
        invert-x;
        invert-y;
    };

    bme688: bme688@76 {
        compatible = "bosch,bme680";
        reg = <0x76>;
    };

    lis2mdl: lis2mdl@1e {
        compatible = "st,lis2mdl";
        reg = <0x1e>;
        irq-gpios = <&gpio0 24 0>;
    };

    bmp581: bmp581@47 {
        compatible = "bosch,bmp581";
        reg = <0x47>;
        int-gpios = <&gpio1 25 (GPIO_PULL_UP | GPIO_ACTIVE_LOW)>;
    };
};

&i2c2 {
    compatible = "nordic,nrf-twim";
    status = "okay";
    clock-frequency = <I2C_BITRATE_FAST>;
    pinctrl-0 = <&i2c2_default>;
    pinctrl-1 = <&i2c2_sleep>;
    pinctrl-names = "default", "sleep";

    cst816s: cst816s@15 {
        compatible = "hynitron,cst816s";
        reg = <0x15>;
        irq-gpios = <&gpio1 0 GPIO_ACTIVE_LOW>;
        rst-gpios = <&gpio0 20 GPIO_ACTIVE_LOW>;
    };
};

&i2c3_default {
    status = "okay";
};

&i2c3_default {
	group1 {
		bias-pull-up;
	};
};


&spi4  {
    status = "okay";
    compatible = "nordic,nrf-spim";
    pinctrl-0 = <&spi4_default>;
    pinctrl-1 = <&spi4_sleep>;
    pinctrl-names = "default", "sleep";
    cs-gpios = <&gpio0 6 GPIO_ACTIVE_LOW>;

    gc9a01: gc9a01@0 {
        compatible = "buydisplay,gc9a01";
        status = "okay";
        spi-max-frequency = <8000000>;
        reg = <0>;
        width = <240>;
        height = <240>;
        bl-gpios = <&gpio1 6 GPIO_ACTIVE_HIGH>; // Backlight not supported on DK. Must connect to 3V3 directly!
        reset-gpios = <&gpio0 25 GPIO_ACTIVE_HIGH>;
        dc-gpios = <&gpio0 7 GPIO_ACTIVE_HIGH>;
    };
};


/ {
	fstab {
		compatible = "zephyr,fstab";
		lvgl_lfs: lvgl_lfs {
			compatible = "zephyr,fstab,littlefs";
			mount-point = "/lvgl_lfs";
			partition = <&littlefs_storage>;
			automount;
			read-size = <1024>;
			prog-size = <512>;
			cache-size = <4096>;
			lookahead-size = <4096>;
			block-cycles = <512>;
		};
	};
};

/delete-node/ &storage_partition;

&mx25r64 {
	partitions {
		compatible = "fixed-partitions";
		#address-cells = <1>;
		#size-cells = <1>;

		littlefs_storage: partition@0 {
			label = "littlefs_storage";
			reg = <0x00000000 0x00200000>;
		};
		lvgl_raw_partition: partition@200000 {
			label = "lvgl_raw_partition";
			reg = <0x00200000 0x00200000>;
		};
        storage_partition: partition@400000 {
            label = "storage_partition";
            reg = <0x400000 0x100000 >;
        };
	};
};

/ {
    sram@2007DFFF {
        compatible = "zephyr,memory-region", "mmio-sram";
        reg = <0x2007DFFF 0x2000>;
        zephyr,memory-region = "RetainedMem";
        status = "okay";

        retainedmem {
            compatible = "zephyr,retained-ram";
            status = "okay";
            #address-cells = <1>;
            #size-cells = <1>;

            retention_coredump: retention@0 {
                compatible = "zephyr,retention";
                status = "okay";
                reg = <0x0 0x1F00>;
                prefix = [04 fa];
                checksum = <1>;
            };

            retention0: retention@1F00 {
                compatible = "zephyr,retention";
                status = "okay";
                reg = <0x1F00 0xFB>;
                prefix = [04 fa];
                checksum = <1>;
            };
            // Last byte in RAM is for boot mode.
            // Du to debugger only supports writing 4 bytes at a time
            // we need to leave a 3 byte gap between the two retention areas.
            retention1: retention@1FFF {
                compatible = "zephyr,retention";
                status = "okay";
                reg = <0x1FFF 0x1>;
            };
        };
    };

    chosen {
            zephyr,boot-mode = &retention1;
    };
};

/*
* Reduce SRAM0 usage by 256 bytes to account for non-init area.
* The last 256 bytes of SRAM0 are used for retention memory.
*/
&sram0 {
    reg = <0x20000000 0x7DFFF>;
};
```

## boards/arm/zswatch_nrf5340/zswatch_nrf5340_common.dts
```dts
/*
 * Copyright (c) 2023 Jakob Krantz
 *
 * SPDX-License-Identifier: Apache-2.0
 */
#include "zswatch_nrf5340_common-pinctrl.dtsi"
#include <zephyr/dt-bindings/input/input-event-codes.h>

/ {
    chosen {
        zephyr,bt-hci-ipc = &ipc0;
        zephyr,ieee802154 = &ieee802154;
        zephyr,display = &gc9a01;
    };

    pwmleds {
        compatible = "pwm-leds";
        display_blk: pwm_led_0 {
            pwms = <&pwm0 0 PWM_USEC(15) PWM_POLARITY_INVERTED>;
        };
        vibrator_pwm: pwm_led_1 {
            pwms = <&pwm1 0 PWM_MSEC(20) 0>;
        };
    };

    lvgl_pointer_input: lvgl_pointer {
        compatible = "zephyr,lvgl-pointer-input";
        input = <&cst816s>;
        swap-xy;
        invert-x;
    };


    aliases {
        display-blk = &display_blk;
        vibrator-pwm = &vibrator_pwm;
        sw1 = &button1;
        sw2 = &button2;
        sw3 = &button3;
        sw4 = &button4;
        watchdog0 = &wdt0;
        mcuboot-button1 = &button1;
    };
};

&pwm0 {
    status = "okay";
    pinctrl-0 = <&pwm0_default>;
    pinctrl-1 = <&pwm0_sleep>;
    pinctrl-names = "default", "sleep";
};

&pwm1 {
    status = "okay";
    pinctrl-0 = <&pwm1_default>;
    pinctrl-1 = <&pwm1_sleep>;
    pinctrl-names = "default", "sleep";
};

&adc {
    status = "okay";
};

&gpiote {
    status = "okay";
};

&gpio0 {
    status = "okay";
    sense-edge-mask = <0xffffffff>;
};

&gpio1 {
    status = "okay";
};

&i2c1 {
    compatible = "nordic,nrf-twim";
    status = "okay";
    clock-frequency = <I2C_BITRATE_FAST>;
    zephyr,concat-buf-size = <512>;

    pinctrl-0 = <&i2c1_default>;
    pinctrl-1 = <&i2c1_sleep>;
    pinctrl-names = "default", "sleep";
    
    bme688: bme688@76 {
        compatible = "bosch,bme680";
        reg = <0x76>;
        status = "disabled";
    };

    lis2mdl: lis2mdl@1e {
        compatible = "st,lis2mdl";
        reg = <0x1e>;
        status = "okay";
        irq-gpios = <&gpio0 24 0>;
        cancel-offset;
    };

    bmp581: bmp581@47 {
        compatible = "bosch,bmp581";
        reg = <0x47>;
        status = "okay";
        int-gpios = <&gpio0 25 (GPIO_PULL_UP | GPIO_ACTIVE_LOW)>;
    };
};

&i2c2 {
    compatible = "nordic,nrf-twim";
    status = "okay";
    clock-frequency = <I2C_BITRATE_FAST>;

    pinctrl-0 = <&i2c2_default>;
    pinctrl-1 = <&i2c2_sleep>;
    pinctrl-names = "default", "sleep";

    cst816s: cst816s@15 {
        compatible = "hynitron,cst816s";
        reg = <0x15>;
        status = "okay";
        irq-gpios = <&gpio1 0 GPIO_ACTIVE_LOW>;
        rst-gpios = <&gpio0 20 GPIO_ACTIVE_LOW>;
    };
};

&timer0 {
    status = "okay";
};

&timer1 {
    status = "disabled";
};

&timer2 {
    status = "okay";
};

&flash0 {
    partitions {
        compatible = "fixed-partitions";
        #address-cells = <1>;
        #size-cells = <1>;

        boot_partition: partition@0 {
            label = "mcuboot";
            reg = <0x00000000 0x00010000>;
        };
        slot0_partition: partition@10000 {
            label = "image-0";
        };
        slot0_ns_partition: partition@50000 {
            label = "image-0-nonsecure";
        };
        slot1_partition: partition@80000 {
            label = "image-1";
        };
        slot1_ns_partition: partition@c0000 {
            label = "image-1-nonsecure";
        };
        scratch_partition: partition@f0000 {
            label = "image-scratch";
            reg = <0x000f0000 0xa000>;
        };
        storage_partition: partition@fa000 {
            label = "storage";
            reg = <0x000fa000 0x00006000>;
        };
    };
};

zephyr_udc0: &usbd {
    compatible = "nordic,nrf-usbd";
    status = "okay";
};

/ {
    reserved-memory {
        #address-cells = <1>;
        #size-cells = <1>;
        ranges;

        sram0_image: image@20000000 {
            /* Zephyr image(s) memory */
        };

        sram0_s: image_s@20000000 {
            /* Secure image memory */
        };

        sram0_ns: image_ns@20040000 {
            /* Non-Secure image memory */
        };
    };
};

/ {
    sram@2007DFFF {
        compatible = "zephyr,memory-region", "mmio-sram";
        reg = <0x2007DFFF 0x2000>;
        zephyr,memory-region = "RetainedMem";
        status = "okay";

        retainedmem {
            compatible = "zephyr,retained-ram";
            status = "okay";
            #address-cells = <1>;
            #size-cells = <1>;

            retention_coredump: retention@0 {
                compatible = "zephyr,retention";
                status = "okay";
                reg = <0x0 0x1F00>;
                prefix = [04 fa];
                checksum = <1>;
            };

            retention0: retention@1F00 {
                compatible = "zephyr,retention";
                status = "okay";
                reg = <0x1F00 0xFB>;
                prefix = [04 fa];
                checksum = <1>;
            };
            // Last byte in RAM is for boot mode.
            // Du to debugger only supports writing 4 bytes at a time
            // we need to leave a 3 byte gap between the two retention areas.
            retention1: retention@1FFF {
                compatible = "zephyr,retention";
                status = "okay";
                reg = <0x1FFF 0x1>;
            };
        };
    };

    chosen {
            zephyr,boot-mode = &retention1;
    };
};

/*
* Reduce SRAM0 usage by 256 bytes to account for non-init area.
* The last 256 bytes of SRAM0 are used for retention memory.
*/
&sram0 {
    reg = <0x20000000 0x7DFFF>;
};

/* Include partition configuration file */
#include "zswatch_nrf5340_partition_conf.dts"
```

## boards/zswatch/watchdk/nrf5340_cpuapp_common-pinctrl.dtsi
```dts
/*
 * Copyright (c) 2025 ZSWatch Project
 * SPDX-License-Identifier: Apache-2.0
 */

 &pinctrl {
    i2c2_default: i2c2_default {
        group1 {
            psels = <NRF_PSEL(TWIM_SDA, 0, 2)>,
                    <NRF_PSEL(TWIM_SCL, 1, 1)>;
        };
    };

    i2c2_sleep: i2c2_sleep {
        group1 {
            psels = <NRF_PSEL(TWIM_SDA, 0, 2)>,
                    <NRF_PSEL(TWIM_SCL, 1, 1)>;
            low-power-enable;
        };
    };

    spi4_default: spi4_default {
        group1 {
            psels = <NRF_PSEL(SPIM_SCK, 0, 8)>,
                    <NRF_PSEL(SPIM_MOSI, 0, 9)>,
                    <NRF_PSEL(SPIM_MISO, 0, 31)>; // TODO: Assigned to an unused pin. Test to remove it!
        };
    };

    spi4_sleep: spi4_sleep {
        group1 {
            psels = <NRF_PSEL(SPIM_SCK, 0, 8)>,
                    <NRF_PSEL(SPIM_MOSI, 0, 9)>,
                    <NRF_PSEL(SPIM_MISO, 0, 31)>; // TODO: Assigned to an unused pin. Test to remove it!
            low-power-enable;
        };
    };

    uart0_default: uart0_default {
        group1 {
            psels = <NRF_PSEL(UART_RX, 1, 11)>;
            psels = <NRF_PSEL(UART_TX, 1, 12)>;
        };
    };

    uart0_sleep: uart0_sleep {
        group1 {
            psels = <NRF_PSEL(UART_RX, 1, 11)>;
            psels = <NRF_PSEL(UART_TX, 1, 12)>;
            low-power-enable;
        };
    };
};
```

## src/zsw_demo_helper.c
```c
#include "zsw_demo_helper.h"
#include "events/ble_event.h"
#include "events/accel_event.h"
#include "ble/ble_comm.h"
#include "zephyr/zbus/zbus.h"
#include "managers/zsw_notification_manager.h"

ZBUS_CHAN_DECLARE(ble_comm_data_chan);
ZBUS_CHAN_DECLARE(accel_data_chan);

static void demo_work_handler(struct k_work *work);

K_WORK_DELAYABLE_DEFINE(demo_work, demo_work_handler);

int step_counter = 50;

static void demo_work_handler(struct k_work *work)
{
    zsw_imu_evt_t evt;

    evt.type = ZSW_IMU_EVT_TYPE_STEP;
    evt.data.step.count = step_counter++;

    zbus_chan_pub(&accel_data_chan, &evt, K_MSEC(250));

    k_work_reschedule(&demo_work, K_SECONDS(2));
}

void zsw_demo_helper_run(void)
{
    zsw_not_mngr_notification_t notification1 = {
        .id = 1,
        .title = "Interested?",
        .body = "Recruiter blah blah",
        .src = NOTIFICATION_SRC_LINKEDIN
    };

    zsw_notification_manager_add(&notification1);

    zsw_not_mngr_notification_t notification2 = {
        .id = 2,
        .title = "mail@jakobkrantz.se",
        .body = "Such a nice email!",
        .src = NOTIFICATION_SRC_GMAIL
    };

    zsw_notification_manager_add(&notification2);

    zsw_not_mngr_notification_t notification3 = {
        .id = 3,
        .title = "Meeting",
        .body = "Don't forget about the meeting tomorrow.",
        .src = NOTIFICATION_SRC_CALENDAR
    };

    zsw_notification_manager_add(&notification3);

    zsw_not_mngr_notification_t notification4 = {
        .id = 4,
        .title = "Sofia",
        .body = "When are you home for dinner?",
        .src = NOTIFICATION_SRC_FB_MESSENGER
    };

    zsw_notification_manager_add(&notification4);

    zsw_not_mngr_notification_t notification5 = {
        .id = 5,
        .title = "New video",
        .body = "Check out this new video.",
        .src = NOTIFICATION_SRC_YOUTUBE
    };

    zsw_notification_manager_add(&notification5);

    zsw_not_mngr_notification_t notification6 = {
        .id = 6,
        .title = "Must watch",
        .body = "Funny cat video!",
        .src = NOTIFICATION_SRC_REDDIT
    };

    zsw_notification_manager_add(&notification6);

    struct ble_data_event evt;

    evt.data.type = BLE_COMM_DATA_TYPE_WEATHER;
    evt.data.data.weather.humidity = 67;
    evt.data.data.weather.weather_code = 801;
    evt.data.data.weather.temperature_c = 12;
    strcpy(evt.data.data.weather.report_text, "Cloudy");

    zbus_chan_pub(&ble_comm_data_chan, &evt, K_MSEC(250));

    k_work_schedule(&demo_work, K_SECONDS(1));
}
```

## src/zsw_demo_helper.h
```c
void zsw_demo_helper_run(void);
```
